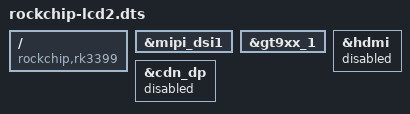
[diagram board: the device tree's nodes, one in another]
/dts-v1/;
/plugin/;

/ {
        compatible = "rockchip,rk3399";
        fragment@0 {
                target = <&mipi_dsi1>;
                __overlay__ {
                        status = "okay";
                };
        };
        fragment@1 {
                target = <&gt9xx_1>;
                __overlay__ {
                        status = "okay";
                };
        };
        fragment@2 {
                target = <&cdn_dp>;
                __overlay__ {
                        status = "disabled";
                };
        };
        fragment@3 {
                target = <&hdmi>;
                __overlay__ {
                        status = "disabled";
                };
        };
};
